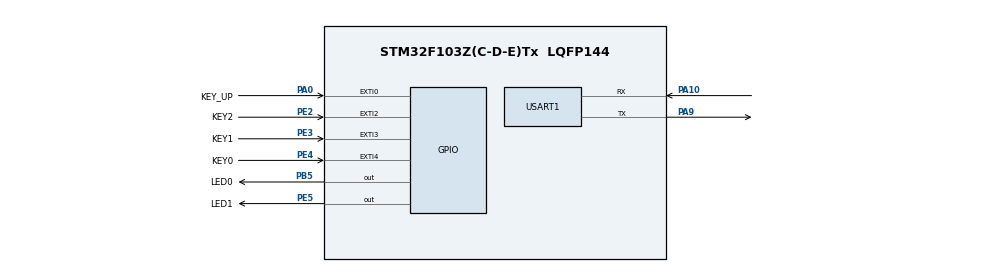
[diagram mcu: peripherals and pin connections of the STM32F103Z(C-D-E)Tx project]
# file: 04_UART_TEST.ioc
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Dma.Request0=USART1_TX
Dma.Request1=USART1_RX
Dma.USART1_RX.1.Direction=DMA_PERIPH_TO_MEMORY
Dma.USART1_RX.1.Instance=DMA1_Channel5
Dma.USART1_RX.1.MemDataAlignment=DMA_MDATAALIGN_BYTE
Dma.USART1_RX.1.MemInc=DMA_MINC_ENABLE
Dma.USART1_RX.1.Mode=DMA_NORMAL
Dma.USART1_RX.1.PeriphDataAlignment=DMA_PDATAALIGN_BYTE
Dma.USART1_RX.1.PeriphInc=DMA_PINC_DISABLE
Dma.USART1_RX.1.Priority=DMA_PRIORITY_LOW
Dma.USART1_TX.0.Direction=DMA_MEMORY_TO_PERIPH
Dma.USART1_TX.0.Instance=DMA1_Channel4
Dma.USART1_TX.0.MemDataAlignment=DMA_MDATAALIGN_BYTE
Dma.USART1_TX.0.MemInc=DMA_MINC_ENABLE
Dma.USART1_TX.0.Mode=DMA_NORMAL
Dma.USART1_TX.0.PeriphDataAlignment=DMA_PDATAALIGN_BYTE
Dma.USART1_TX.0.PeriphInc=DMA_PINC_DISABLE
Dma.USART1_TX.0.Priority=DMA_PRIORITY_LOW
Mcu.Family=STM32F1
Mcu.Name=STM32F103Z(C-D-E)Tx
Mcu.Package=LQFP144
NVIC.DMA1_Channel4_IRQn=true\:0\:0\:false\:false\:true\:false\:true\:true
NVIC.DMA1_Channel5_IRQn=true\:0\:0\:false\:false\:true\:false\:true\:true
NVIC.EXTI0_IRQn=true\:4\:0\:true\:false\:true\:true\:true\:true
NVIC.EXTI2_IRQn=true\:4\:0\:true\:false\:true\:true\:true\:true
NVIC.EXTI3_IRQn=true\:4\:0\:true\:false\:true\:true\:true\:true
NVIC.EXTI4_IRQn=true\:4\:0\:true\:false\:true\:true\:true\:true
NVIC.PriorityGroup=NVIC_PRIORITYGROUP_4
NVIC.TIM6_IRQn=true\:0\:0\:true\:false\:true\:true\:true\:true
NVIC.USART1_IRQn=true\:0\:0\:false\:false\:true\:true\:true\:true
OSC_IN.Mode=HSE-External-Oscillator
OSC_IN.Signal=RCC_OSC_IN
OSC_OUT.Mode=HSE-External-Oscillator
OSC_OUT.Signal=RCC_OSC_OUT
PA0-WKUP.GPIO_Label=KEY_UP
PA0-WKUP.GPIO_ModeDefaultEXTI=GPIO_MODE_IT_RISING_FALLING
PA0-WKUP.GPIO_PuPd=GPIO_PULLDOWN
PA0-WKUP.Signal=GPXTI0
PA10.Mode=Asynchronous
PA10.Signal=USART1_RX
PA13.Mode=Serial_Wire
PA13.Signal=SYS_JTMS-SWDIO
PA14.Mode=Serial_Wire
PA14.Signal=SYS_JTCK-SWCLK
PA9.Mode=Asynchronous
PA9.Signal=USART1_TX
PB5.GPIO_Label=LED0
PB5.GPIO_PuPd=GPIO_NOPULL
PB5.PinState=GPIO_PIN_SET
PB5.Signal=GPIO_Output
PC14-OSC32_IN.Mode=LSE-External-Oscillator
PC14-OSC32_IN.Signal=RCC_OSC32_IN
PC15-OSC32_OUT.Mode=LSE-External-Oscillator
PC15-OSC32_OUT.Signal=RCC_OSC32_OUT
PE2.GPIO_Label=KEY2
PE2.GPIO_ModeDefaultEXTI=GPIO_MODE_IT_RISING_FALLING
PE2.GPIO_PuPd=GPIO_PULLUP
PE2.Signal=GPXTI2
PE3.GPIO_Label=KEY1
PE3.GPIO_ModeDefaultEXTI=GPIO_MODE_IT_RISING_FALLING
PE3.GPIO_PuPd=GPIO_PULLUP
PE3.Signal=GPXTI3
PE4.GPIO_Label=KEY0
PE4.GPIO_ModeDefaultEXTI=GPIO_MODE_IT_RISING_FALLING
PE4.GPIO_PuPd=GPIO_PULLUP
PE4.Signal=GPXTI4
PE5.GPIO_Label=LED1
PE5.PinState=GPIO_PIN_SET
PE5.Signal=GPIO_Output
ProjectManager.HeapSize=0x200
ProjectManager.StackSize=0x400
ProjectManager.TargetToolchain=MDK-ARM V5
RCC.AHBFreq_Value=72000000
RCC.APB1CLKDivider=RCC_HCLK_DIV2
RCC.APB1Freq_Value=36000000
RCC.APB1TimFreq_Value=72000000
RCC.APB2Freq_Value=72000000
RCC.APB2TimFreq_Value=72000000
RCC.HCLKFreq_Value=72000000
RCC.PLLMUL=RCC_PLL_MUL9
RCC.PLLSourceVirtual=RCC_PLLSOURCE_HSE
RCC.SYSCLKFreq_VALUE=72000000
RCC.SYSCLKSource=RCC_SYSCLKSOURCE_PLLCLK
RCC.USBFreq_Value=72000000
TIM6.AutoReloadPreload=TIM_AUTORELOAD_PRELOAD_ENABLE
TIM6.Period=99
TIM6.Prescaler=71
TIM6.TIM_MasterOutputTrigger=TIM_TRGO_UPDATE
USART1.VirtualMode=VM_ASYNC
VP_TIM6_VS_ClockSourceINT.Mode=Enable_Timer
board=custom

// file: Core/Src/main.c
/* USER CODE BEGIN Header */
/**
  ******************************************************************************
  * @file           : main.c
  * @brief          : Main program body
  ******************************************************************************
  * @attention
  *
  * Copyright (c) 2025 STMicroelectronics.
  * All rights reserved.
  *
  * This software is licensed under terms that can be found in the LICENSE file
  * in the root directory of this software component.
  * If no LICENSE file comes with this software, it is provided AS-IS.
  *
  ******************************************************************************
  */
/* USER CODE END Header */
#include "main.h"
#include "dma.h"
#include "tim.h"
#include "usart.h"
#include "gpio.h"

/* USER CODE BEGIN Includes */
#include "debug.h"
/* USER CODE END Includes */

void SystemClock_Config(void);

int main(void)
{

  /* USER CODE BEGIN 1 */
	uint8_t x = 10;
  /* USER CODE END 1 */

  /* MCU Configuration--------------------------------------------------------*/

  /* Reset of all peripherals, Initializes the Flash interface and the Systick. */
  HAL_Init();

  /* Configure the system clock */
  SystemClock_Config();

  /* Initialize all configured peripherals */
  MX_GPIO_Init();
  MX_DMA_Init();
  MX_TIM6_Init();
  MX_USART1_UART_Init();
  /* USER CODE BEGIN 2 */
	LL_TIM_EnableCounter(TIM6);
	LL_TIM_EnableIT_UPDATE(TIM6);
  /* USER CODE END 2 */

  /* Infinite loop */
  /* USER CODE BEGIN WHILE */
  while (1)
  {
		debug("%d\n", x);
		LL_mDelay(100);
    /* USER CODE END WHILE */

  }
}

void SystemClock_Config(void)
{
  LL_FLASH_SetLatency(LL_FLASH_LATENCY_2);
  while(LL_FLASH_GetLatency()!= LL_FLASH_LATENCY_2)
  {
  }
  LL_RCC_HSE_Enable();

   /* Wait till HSE is ready */
  while(LL_RCC_HSE_IsReady() != 1)
  {

  }
  LL_RCC_PLL_ConfigDomain_SYS(LL_RCC_PLLSOURCE_HSE_DIV_1, LL_RCC_PLL_MUL_9);
  LL_RCC_PLL_Enable();

   /* Wait till PLL is ready */
  while(LL_RCC_PLL_IsReady() != 1)
  {

  }
  LL_RCC_SetAHBPrescaler(LL_RCC_SYSCLK_DIV_1);
  LL_RCC_SetAPB1Prescaler(LL_RCC_APB1_DIV_2);
  LL_RCC_SetAPB2Prescaler(LL_RCC_APB2_DIV_1);
  LL_RCC_SetSysClkSource(LL_RCC_SYS_CLKSOURCE_PLL);

   /* Wait till System clock is ready */
  while(LL_RCC_GetSysClkSource() != LL_RCC_SYS_CLKSOURCE_STATUS_PLL)
  {

  }
  LL_SetSystemCoreClock(72000000);

   /* Update the time base */
  if (HAL_InitTick (TICK_INT_PRIORITY) != HAL_OK)
  {
    Error_Handler();
  }
}

void Error_Handler(void)
{
  __disable_irq();
  while (1)
  {
  }
}
